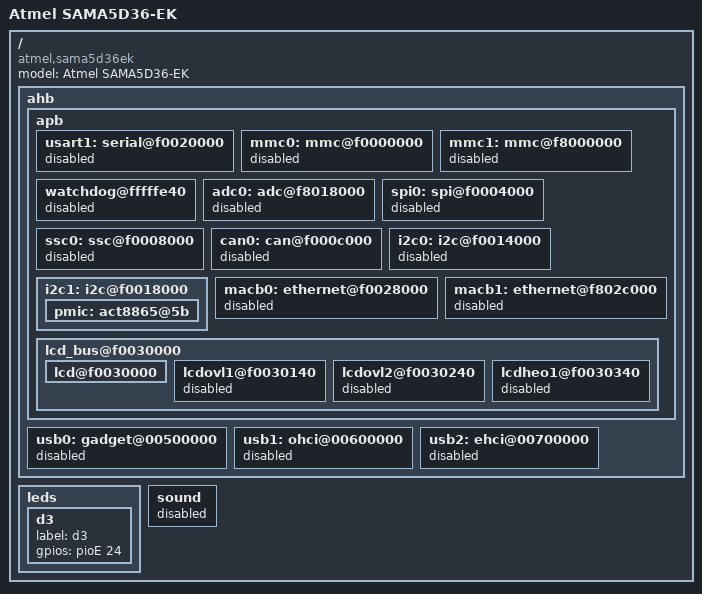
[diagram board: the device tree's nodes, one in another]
/*
 * sama5d35ek_pda7_lcd.dts - Device Tree file for SAMA5D36-EK with pda7 board to test lcd pm
 *
 *  Copyright (C) 2013 Atmel
 *
 * Licensed under GPLv2 or later.
 */
/dts-v1/;
#include "sama5d3xmb.dtsi"
#include "sama5d3xdm_pda7.dtsi"

/ {
	model = "Atmel SAMA5D36-EK";
	compatible = "atmel,sama5d36ek", "pda,tm70xx", "atmel,sama5d3xmb", "atmel,sama5d3xcm", "atmel,sama5d3", "atmel,sama5";

	ahb {
		apb {
			usart1: serial@f0020000 {
				status = "disabled";
			};

			mmc0: mmc@f0000000 {
				status = "disabled";
			};

			mmc1: mmc@f8000000 {
				status = "disabled";
			};

			watchdog@fffffe40 {
				status = "disabled";
			};

			adc0: adc@f8018000 {
				status = "disabled";
			};

			spi0: spi@f0004000 {
				status = "disabled";
			};

			ssc0: ssc@f0008000 {
				status = "disabled";
			};

			can0: can@f000c000 {
				status = "disabled";
			};

			i2c0: i2c@f0014000 {
				status = "disabled";
			};

			i2c1: i2c@f0018000 {
				status = "okay";
				pmic: act8865@5b {
					status = "okay";
				};
			};

			macb0: ethernet@f0028000 {
				status = "disabled";
			};

			macb1: ethernet@f802c000 {
				status = "disabled";
			};

			lcd_bus@f0030000 {
				status = "okay";

				lcd@f0030000 {
					status = "okay";
				};

				lcdovl1@f0030140 {
					status = "disabled";
				};

				lcdovl2@f0030240 {
					status = "disabled";
				};

				lcdheo1@f0030340 {
					status = "disabled";
				};
			};
		};

		usb0: gadget@00500000 {
			status = "disabled";
		};

		usb1: ohci@00600000 {
			status = "disabled";
		};

		usb2: ehci@00700000 {
			status = "disabled";
		};
	};

	leds {
		d3 {
			label = "d3";
			gpios = <&pioE 24 GPIO_ACTIVE_HIGH>;
		};
	};

	sound {
		status = "disabled";
	};
};
